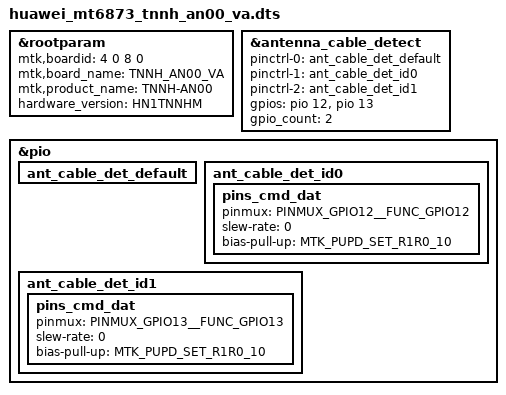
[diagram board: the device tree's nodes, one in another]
#include <dt-bindings/interrupt-controller/arm-gic.h>
#include <dt-bindings/interrupt-controller/irq.h>
#include <dt-bindings/pinctrl/mt6873-pinfunc.h>
#include <dt-bindings/clock/mt6873-clk.h>
/dts-v1/;
/plugin/;

#include "huawei_common/huawei_common.dtsi"
#include "huawei_mt6873_tnnh_an00_va/huawei.dtsi"

&rootparam {
    mtk,boardid = <4 0 8 0>;
    mtk,board_name = "TNNH_AN00_VA";
    mtk,product_name = "TNNH-AN00";
    hardware_version = "HN1TNNHM";
};

&antenna_cable_detect {
	pinctrl-names = "default", "id0", "id1";
	pinctrl-0 = <&ant_cable_det_default>;
	pinctrl-1 = <&ant_cable_det_id0>;
	pinctrl-2 = <&ant_cable_det_id1>;
	gpios = <&pio 12 0 >,
		<&pio 13 0 >;
	gpio_count = <2>;
};

&pio {
	ant_cable_det_default: ant_cable_det_default {
	};

	ant_cable_det_id0: ant_cable_det_id0 {
		pins_cmd_dat {
			pinmux = <PINMUX_GPIO12__FUNC_GPIO12>;
			slew-rate = <0>;
			bias-pull-up = <MTK_PUPD_SET_R1R0_10>;
		};
	};
	ant_cable_det_id1: ant_cable_det_id1 {
		pins_cmd_dat {
			pinmux = <PINMUX_GPIO13__FUNC_GPIO13>;
			slew-rate = <0>;
			bias-pull-up = <MTK_PUPD_SET_R1R0_10>;
		};
	};
};

#include <k6873v1_64/cust.dtsi>

/*End of this file, DO NOT ADD ANYTHING HERE*/
